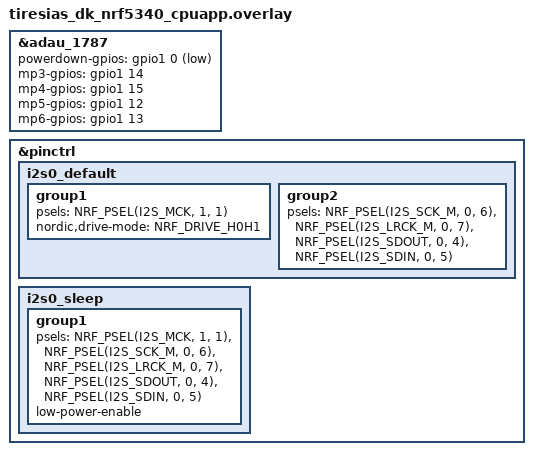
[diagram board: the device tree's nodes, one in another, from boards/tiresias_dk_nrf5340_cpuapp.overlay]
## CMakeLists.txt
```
#
# Copyright (c) 2022 Nordic Semiconductor ASA
#
# SPDX-License-Identifier: LicenseRef-Nordic-5-Clause
#

cmake_minimum_required(VERSION 3.20.0)

# Flag which defines whether application is compiled as gateway/dongle or headset
add_compile_definitions(HEADSET=1)
add_compile_definitions(GATEWAY=2)

find_package(Zephyr REQUIRED HINTS $ENV{ZEPHYR_BASE})

project(new-tiresias)

# The HA soak profile only programs the ADAU1787 and then lets the application
# core fall through to Zephyr's idle thread. Keep the normal application source
# graph untouched for the BLE profiles.
if(CONFIG_TIRESIAS_SOAK_PROFILE_HA)
  target_sources(app PRIVATE src/modes/main_ha.c)

  zephyr_library_include_directories(
      src/drivers
      src/utils/macros
      src/SigmaStudioFiles
  )

  add_subdirectory(src/drivers)
  add_subdirectory(src/SigmaStudioFiles)
elseif(CONFIG_TIRESIAS_SOAK_PROFILE_ADAU_PD)
  target_sources(app PRIVATE src/modes/main_adau_pd.c)
elseif(CONFIG_TIRESIAS_SOAK_PROFILE_ADAU_AWAKE_IDLE)
  target_sources(app PRIVATE src/modes/main_adau_awake_idle.c)
elseif(CONFIG_TIRESIAS_SOAK_PROFILE_BASELINE)
  target_sources(app PRIVATE src/modes/main_baseline.c)
else()
  string(TIMESTAMP NRF5340_AUDIO_CORE_APP_COMP_DATE "%a %b %d %H:%M:%S %Y")

# Generate fw_info_app.c
configure_file("${CMAKE_CURRENT_SOURCE_DIR}/src/utils/fw_info_app.c.in"
               "${CMAKE_BINARY_DIR}/fw_info_app.c"
               @ONLY)

# Target sources below are specific to the nRF5340 Audio DK HW
target_sources(app PRIVATE
    ${CMAKE_BINARY_DIR}/fw_info_app.c
    )

target_sources(app PRIVATE src/main.c)

# Include application events and configuration headers
zephyr_library_include_directories(
    include
    src/audio
    src/application
    src/bluetooth
    src/drivers
    src/modules
    src/utils
    src/utils/macros
    src/SigmaStudioFiles
)

zephyr_library_include_directories(app PRIVATE
    ${ZEPHYR_NRF_MODULE_DIR}/boards/arm/nrf5340_audio_dk_nrf5340)

# Application sources
add_subdirectory(src/audio)
add_subdirectory(src/application)
add_subdirectory(src/bluetooth)
add_subdirectory(src/drivers)
add_subdirectory(src/modules)
add_subdirectory(src/utils)
add_subdirectory(src/SigmaStudioFiles)
endif()
```

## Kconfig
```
#
# Copyright (c) 2018 Nordic Semiconductor ASA
#
# SPDX-License-Identifier: LicenseRef-Nordic-5-Clause
#

config TIRESIAS_SOAK_PROFILE_HA
	bool "Minimal hearing-aid soak-test image"
	help
	  Program the ADAU1787 over I2C and then leave the nRF5340 application
	  core idle with the I2C controller suspended. Bluetooth, the network core
	  and the nRF I2S peripheral are intentionally not part of this profile;
	  the ADAU1787 receives MCLK from the board's external oscillator.

config TIRESIAS_SOAK_PROFILE_BASELINE
	bool "VDD-domain baseline soak-test image"
	help
	  Leave the ADAU1787 untouched and return immediately to the Zephyr idle
	  thread. This profile is intended for direct-VDD measurements on the board
	  without the PMIC, before enabling VSYS/AVDD-dependent circuitry.

config TIRESIAS_SOAK_PROFILE_ADAU_PD
	bool "ADAU1787 power-down soak-test image"
	help
	  Keep all board supply rails present, explicitly assert the active-low
	  ADAU1787 !PD input, initialize and suspend the control I2C bus, and then
	  leave the nRF5340 application core idle. This profile performs no I2C
	  transfer and does not download a SigmaStudio program.

config TIRESIAS_SOAK_PROFILE_ADAU_AWAKE_IDLE
	bool "ADAU1787 awake-idle soak-test image"
	help
	  Release the active-low ADAU1787 !PD input, retain control-port access,
	  explicitly disable every block-level power control, suspend the I2C bus,
	  and then leave the nRF5340 application core idle. No SigmaStudio program
	  is downloaded.

config TIRESIAS_HA_INPUT_ADC
	int "ADAU1787 analog input used by the HA soak profile"
	depends on TIRESIAS_SOAK_PROFILE_HA
	range 0 1
	default 0
	help
	  Select ADC0/MICBIAS0 for the MIC0_OUT microphone or ADC1/MICBIAS1 for
	  MIC1_OUT. The Tiresias microphones are wired to AIN0 and AIN1.

config TIRESIAS_HA_OUTPUT_DAC
	int "ADAU1787 mono playback channel used by the HA soak profile"
	depends on TIRESIAS_SOAK_PROFILE_HA
	range 0 1
	default 0
	help
	  Select playback/headphone channel 0 or 1. The other channel is muted and
	  powered down after the SigmaStudio download.

menuconfig NRF5340_AUDIO
	 bool "nRF5340 Audio [EXPERIMENTAL]"
	 depends on !TIRESIAS_SOAK_PROFILE_HA && !TIRESIAS_SOAK_PROFILE_BASELINE && !TIRESIAS_SOAK_PROFILE_ADAU_PD && !TIRESIAS_SOAK_PROFILE_ADAU_AWAKE_IDLE
	 select EXPERIMENTAL

if NRF5340_AUDIO

config CUSTOM_BROADCASTER
	bool "Allow custom broadcasters"
	default n
	help
	  Incomplete feature for now, but will introduce support for multiple BIGs and subgroups.

config AUDIO_DEV
	int "Select which device type to compile for. 1=HEADSET or 2=GATEWAY"
	range 1 2
	default 1
	help
	  Setting this variable to 1 selects that the project is compiled
	  as a HEADSET device.
	  Setting to 2 will compile as a GATEWAY.

choice NRF5340_AUDIO_TRANSPORT_MODE
	prompt "Choose BIS or CIS for ISO transport"
	default TRANSPORT_CIS if WALKIE_TALKIE_DEMO
	default TRANSPORT_CIS

config TRANSPORT_BIS
	bool "Use BIS (Broadcast Isochronous Stream)"

config TRANSPORT_CIS
	bool "Use CIS (Connected Isochronous Stream)"

endchoice

#----------------------------------------------------------------------------#
rsource "Kconfig.defaults"
rsource "src/audio/Kconfig"
rsource "src/bluetooth/Kconfig"
rsource "src/drivers/Kconfig"
rsource "src/modules/Kconfig"
rsource "src/utils/Kconfig"

#----------------------------------------------------------------------------#
menu "Logging"

module = MAIN
module-str = main
source "subsys/logging/Kconfig.template.log_config"

config PRINT_STACK_USAGE_MS
	depends on THREAD_ANALYZER && INIT_STACKS
	int "Print stack usage every x milliseconds"
	default 5000

endmenu # Log levels

#----------------------------------------------------------------------------#
endif # NRF5340_AUDIO

source "Kconfig.zephyr"
```

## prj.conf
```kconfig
#
# Copyright (c) 2024 Nordic Semiconductor ASA
#
# SPDX-License-Identifier: LicenseRef-Nordic-5-Clause
#

# nRF5340 Audio
CONFIG_NRF5340_AUDIO=y
CONFIG_SAMPLE_RATE_CONVERTER=y
CONFIG_SAMPLE_RATE_CONVERTER_FILTER_SIMPLE=y

# General
CONFIG_DEBUG=y
CONFIG_DEBUG_INFO=y
CONFIG_ASSERT=y
CONFIG_STACK_USAGE=y
CONFIG_THREAD_RUNTIME_STATS=y
CONFIG_STACK_SENTINEL=y
CONFIG_INIT_STACKS=y
CONFIG_BT=y

# Uart driver
CONFIG_SERIAL=y

# Logging
CONFIG_LOG=y
CONFIG_NEWLIB_LIBC_FLOAT_PRINTF=y
CONFIG_LOG_TAG_MAX_LEN=2
CONFIG_LOG_TAG_DEFAULT="--"
CONFIG_LOG_BACKEND_UART=n
CONFIG_LOG_BACKEND_RTT=y
CONFIG_LOG_BUFFER_SIZE=4096

# Use this for debugging thread usage
#CONFIG_LOG_THREAD_ID_PREFIX=y

# Console related defines
CONFIG_CONSOLE=y
CONFIG_RTT_CONSOLE=y
CONFIG_UART_CONSOLE=n
CONFIG_SEGGER_RTT_BUFFER_SIZE_UP=8192

# Shell related defines
CONFIG_SHELL=y
CONFIG_KERNEL_SHELL=y
CONFIG_USE_SEGGER_RTT=y
CONFIG_SHELL_BACKEND_RTT=n
CONFIG_SHELL_BACKEND_SERIAL=n
CONFIG_SHELL_VT100_COMMANDS=y
CONFIG_SHELL_VT100_COLORS=y
CONFIG_SHELL_STACK_SIZE=4096
CONFIG_SHELL_CMD_BUFF_SIZE=128
## Reduce shell memory usage
CONFIG_SHELL_WILDCARD=n
CONFIG_SHELL_HELP_ON_WRONG_ARGUMENT_COUNT=n
CONFIG_SHELL_STATS=n
CONFIG_SHELL_CMDS=n
CONFIG_SHELL_HISTORY=y

# Turn off default shell commands
CONFIG_I2C_SHELL=n
CONFIG_HWINFO_SHELL=n
CONFIG_CLOCK_CONTROL_NRF_SHELL=n
CONFIG_FLASH_SHELL=n
CONFIG_DEVICE_SHELL=n

# Suppress LOG_ERR messages from sd_check_card_type. Because SPI_SDHC has no card presence method,
# assume card is in slot. Thus error message is always shown if card is not inserted
CONFIG_SD_LOG_LEVEL_OFF=y

# Suppress LOG_INF messages from hci_core
CONFIG_BT_HCI_CORE_LOG_LEVEL_WRN=y

# DFU
CONFIG_AUDIO_BT_MGMT_DFU=y
CONFIG_MCUMGR_TRANSPORT_BT_PERM_RW=y
CONFIG_BT_L2CAP_TX_MTU=498
CONFIG_BT_BUF_ACL_TX_SIZE=251

# External Flash
CONFIG_FLASH=y
CONFIG_FLASH_MAP=y
CONFIG_SPI_NOR=y
CONFIG_SPI_NOR_SFDP_DEVICETREE=y

# ====================== Broadcast Sink ====================== #

CONFIG_TRANSPORT_BIS=y
CONFIG_AUDIO_DEV=1
CONFIG_BT_DEVICE_NAME="TIRESIAS_BIS_HEADSET"

## ACL related configs ##
CONFIG_BT_OBSERVER=y
CONFIG_BT_PERIPHERAL=y
CONFIG_BT_SMP=y
CONFIG_BT_AUDIO=y
CONFIG_BT_GATT_DYNAMIC_DB=y
CONFIG_BT_GATT_CACHING=n

## Device Information Service
CONFIG_BT_DIS=y
CONFIG_BT_DIS_MANUF_NAME=y
CONFIG_BT_DIS_MANUF_NAME_STR="EESC-USP"
CONFIG_BT_DIS_MODEL_NUMBER=y
CONFIG_BT_DIS_MODEL_NUMBER_STR="Tiresias Hearing Aid"
CONFIG_BT_DIS_FW_REV=y

CONFIG_SETTINGS=y
CONFIG_BT_SETTINGS=y
CONFIG_FLASH=y
CONFIG_FLASH_MAP=y
CONFIG_NVS=y

CONFIG_MBEDTLS_ENABLE_HEAP=y
CONFIG_MBEDTLS_HEAP_SIZE=2048

CONFIG_BT_BUF_ACL_TX_COUNT=18

CONFIG_BT_PERIPHERAL_PREF_MIN_INT=64
CONFIG_BT_PERIPHERAL_PREF_MAX_INT=69
CONFIG_BT_PERIPHERAL_PREF_LATENCY=0
CONFIG_BT_PERIPHERAL_PREF_TIMEOUT=200

# Generic Audio Sink - 0x0840
CONFIG_BT_DEVICE_APPEARANCE=2112
CONFIG_BT_PER_ADV_SYNC_MAX=2

## ISO related configs ##
CONFIG_BT_BAP_BROADCAST_SNK_STREAM_COUNT=2
CONFIG_BT_BAP_BROADCAST_SNK_COUNT=2
CONFIG_BT_ISO_MAX_CHAN=2
CONFIG_BT_ISO_MAX_BIG=2

## PACS related configs ##
CONFIG_BT_PAC_SNK_NOTIFIABLE=y
CONFIG_BT_PAC_SNK=y
CONFIG_BT_PAC_SRC_NOTIFIABLE=y
CONFIG_BT_PAC_SRC=y

## Audio related configs ##
CONFIG_AUDIO_MUTE=n
CONFIG_AUDIO_TEST_TONE=y

CONFIG_BT_ISO_SYNC_RECEIVER=y
CONFIG_BT_BAP_SCAN_DELEGATOR=y
CONFIG_BT_BAP_BROADCAST_SINK=y

## LC3 related configs ##
CONFIG_LC3_DEC_CHAN_MAX=1
```

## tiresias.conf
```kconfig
# I2S
CONFIG_I2S=n
CONFIG_NRFX_I2S0=y
CONFIG_I2S_NRFX=n
CONFIG_SERIAL=y
# Bluetooth
CONFIG_BT=y
CONFIG_BT_PERIPHERAL=y
CONFIG_BT_DEVICE_NAME="Tiresias_DK"
CONFIG_BT_GATT_DYNAMIC_DB=y
CONFIG_BT_SMP=y
## Device Information Service
CONFIG_BT_DIS=y
CONFIG_BT_DIS_MANUF_NAME=y
CONFIG_BT_DIS_MANUF_NAME_STR="EESC-USP"
CONFIG_BT_DIS_MODEL_NUMBER=y
CONFIG_BT_DIS_MODEL_NUMBER_STR="Tiresias Hearing Aid"
CONFIG_BT_DIS_FW_REV=y
## Battery Service
CONFIG_BT_BAS=y
# https://docs.nordicsemi.com/bundle/zephyr-apis-latest/page/group_bt_bas.html
# CONFIG_BT_AUDIO=y
# CONFIG_BT_BAP_BROADCAST_SINK=y
# CONFIG_BT_ISO=y
# MCUMGR
CONFIG_MCUMGR=y
CONFIG_MCUMGR_TRANSPORT_BT=y
CONFIG_MCUMGR_GRP_OS=y
CONFIG_MCUMGR_GRP_IMG=y
CONFIG_MCUMGR_GRP_SHELL=y
CONFIG_STATS=y
CONFIG_MCUMGR_GRP_STAT=y
CONFIG_SHELL=y
CONFIG_BT_SHELL=y
CONFIG_SHELL_BACKEND_DUMMY=y
# GPIO
CONFIG_GPIO=y
# Debug
CONFIG_DEBUG_THREAD_INFO=y
CONFIG_DEBUG_OPTIMIZATIONS=y
# Log
CONFIG_LOG=y
CONFIG_LOG_MODE_DEFERRED=n
# Enable RTT
CONFIG_USE_SEGGER_RTT=y
CONFIG_LOG_BACKEND_RTT=y
CONFIG_LOG_BACKEND_SHOW_COLOR=n
CONFIG_LOG_MODE_IMMEDIATE=n
CONFIG_SEGGER_RTT_BUFFER_SIZE_UP=8192
# Enables console over RTT
CONFIG_RTT_CONSOLE=y
# ZBUS
CONFIG_ZBUS=y
CONFIG_ZBUS_LOG_LEVEL_INF=y
CONFIG_ZBUS_RUNTIME_OBSERVERS=y
# Stacks and heaps
CONFIG_MAIN_STACK_SIZE=16384
CONFIG_HEAP_MEM_POOL_SIZE=16384
# I2C
CONFIG_I2C=y
CONFIG_NRFX_TWIM1=y
CONFIG_NRFX_TIMER1=y
# NFC pins disable
# CONFIG_NFCT_PINS_AS_GPIOS=y
# Storage
CONFIG_FLASH=y
CONFIG_FLASH_MAP=y
CONFIG_NVS=y
CONFIG_MPU_ALLOW_FLASH_WRITE=y
# Tiresias
# CONFIG_NO_AUDIO_CODEC=y
CONFIG_AUDIO_CODEC_ADAU1787=y
# FOTA
CONFIG_NCS_SAMPLE_MCUMGR_BT_OTA_DFU=y
CONFIG_PINCTRL=y
```

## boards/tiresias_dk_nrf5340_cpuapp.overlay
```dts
/* Temporary pin swap until the SPT0 data path is repaired. */

&adau_1787 {
	powerdown-gpios = <&gpio1 0 GPIO_ACTIVE_LOW>;
	mp3-gpios = <&gpio1 14 GPIO_ACTIVE_HIGH>;
	mp4-gpios = <&gpio1 15 GPIO_ACTIVE_HIGH>;
	mp5-gpios = <&gpio1 12 GPIO_ACTIVE_HIGH>;
	mp6-gpios = <&gpio1 13 GPIO_ACTIVE_HIGH>;
};

&pinctrl {
	i2s0_default: i2s0_default {
		group1 {
			psels = <NRF_PSEL(I2S_MCK, 1, 1)>;
			nordic,drive-mode = <NRF_DRIVE_H0H1>;
		};

		group2 {
			psels = <NRF_PSEL(I2S_SCK_M, 0, 6)>,
				<NRF_PSEL(I2S_LRCK_M, 0, 7)>,
				<NRF_PSEL(I2S_SDOUT, 0, 4)>,
				<NRF_PSEL(I2S_SDIN, 0, 5)>;
		};
	};

	i2s0_sleep: i2s0_sleep {
		group1 {
			psels = <NRF_PSEL(I2S_MCK, 1, 1)>,
				<NRF_PSEL(I2S_SCK_M, 0, 6)>,
				<NRF_PSEL(I2S_LRCK_M, 0, 7)>,
				<NRF_PSEL(I2S_SDOUT, 0, 4)>,
				<NRF_PSEL(I2S_SDIN, 0, 5)>;
			low-power-enable;
		};
	};
};
```

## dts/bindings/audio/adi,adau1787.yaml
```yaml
description: Analog Devices ADAU1787 audio codec and DSP

compatible: "adi,adau1787"

include: i2c-device.yaml

properties:
  powerdown-gpios:
    type: phandle-array
    required: true
    description: Active-low ADAU1787 power-down input

  mp3-gpios:
    type: phandle-array
    description: ADAU1787 multipurpose pin 3 connection

  mp4-gpios:
    type: phandle-array
    description: ADAU1787 multipurpose pin 4 connection

  mp5-gpios:
    type: phandle-array
    description: ADAU1787 multipurpose pin 5 connection

  mp6-gpios:
    type: phandle-array
    description: ADAU1787 multipurpose pin 6 connection
```

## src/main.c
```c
/*
 * Copyright (c) 2023 Nordic Semiconductor ASA
 *
 * SPDX-License-Identifier: LicenseRef-Nordic-5-Clause
 */

#include "device_controller.h"
#include "fw_info_app.h"
#include "macros_common.h"
#include "tiresias_dk.h"

#include <zephyr/logging/log.h>

LOG_MODULE_REGISTER(main, CONFIG_MAIN_LOG_LEVEL);

int main(void)
{
  int ret;

  LOG_DBG("Main started");

  ret = tiresias_dk_init();
  ERR_CHK(ret);

  ret = fw_info_app_print();
  ERR_CHK(ret);

  ret = device_controller_run();
  ERR_CHK(ret);

  return ret;
}
```

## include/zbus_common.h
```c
/*
 * Copyright (c) 2023 Nordic Semiconductor ASA
 *
 * SPDX-License-Identifier: LicenseRef-Nordic-5-Clause
 */

#ifndef _ZBUS_COMMON_H_
#define _ZBUS_COMMON_H_

#include <zephyr/bluetooth/audio/audio.h>

#include "le_audio.h"

#define ZBUS_READ_TIMEOUT_MS	K_MSEC(100)
#define ZBUS_ADD_OBS_TIMEOUT_MS K_MSEC(200)

/***** Messages for zbus ******/

/* === Button === */
typedef enum btn_event_t {
	BUTTON_1_PRESSED,
} btn_event_t;
typedef struct btn_chan_msg_t {
	enum btn_event_t event;
} btn_chan_msg_t;

/* === Device Controller subsystem === */
typedef enum device_controller_cmd {
  DEVICE_CONTROLLER_CMD_START,
  DEVICE_CONTROLLER_CMD_LOW_POWER,
  DEVICE_CONTROLLER_CMD_WAKE,
  DEVICE_CONTROLLER_CMD_POWER_OFF,
  DEVICE_CONTROLLER_CMD_RECOVER,
} device_controller_cmd;

typedef struct device_controller_cmd_chan_msg {
  enum device_controller_cmd cmd;
} device_controller_cmd_chan_msg;

typedef enum device_controller_state {
  DEVICE_CONTROLLER_STATE_OFF,
  DEVICE_CONTROLLER_STATE_INITIALIZING,
  DEVICE_CONTROLLER_STATE_OPERATIONAL,
  DEVICE_CONTROLLER_STATE_LOW_POWER,
  DEVICE_CONTROLLER_STATE_FAULT,
} device_controller_state;

typedef struct device_controller_state_chan_msg {
  enum device_controller_state state;
} device_controller_state_chan_msg;

/* === Codec Controller subsystem === */
typedef enum codec_controller_cmd {
  CODEC_CONTROLLER_CMD_INITIALIZE,
  CODEC_CONTROLLER_CMD_SELECT_LOCAL,
  CODEC_CONTROLLER_CMD_SELECT_BROADCAST,
  CODEC_CONTROLLER_CMD_POWER_DOWN,
  CODEC_CONTROLLER_CMD_RESET,
} codec_controller_cmd;

typedef struct codec_controller_cmd_chan_msg {
  enum codec_controller_cmd cmd;
} codec_controller_cmd_chan_msg;

typedef enum codec_controller_state {
  CODEC_CONTROLLER_STATE_OFF,
  CODEC_CONTROLLER_STATE_INITIALIZING,
  CODEC_CONTROLLER_STATE_LOCAL_ONLY,
  CODEC_CONTROLLER_STATE_BROADCAST_ONLY,
  CODEC_CONTROLLER_STATE_ERROR,
} codec_controller_state;

typedef struct codec_controller_state_chan_msg {
  enum codec_controller_state state;
} codec_controller_state_chan_msg;

typedef enum codec_controller_result {
  CODEC_CONTROLLER_RESULT_COMMAND_REJECTED,
  CODEC_CONTROLLER_RESULT_OPERATION_FAILED,
} codec_controller_result;

typedef struct codec_controller_result_chan_msg {
  enum codec_controller_cmd cmd;
  enum codec_controller_result result;
  int error;
} codec_controller_result_chan_msg;

/* === Control Link subsystem === */
typedef enum control_link_cmd {
  CONTROL_LINK_CMD_ENABLE_CONTROL,
  CONTROL_LINK_CMD_DISABLE_CONTROL,
  CONTROL_LINK_CMD_RESET,
} control_link_cmd;

typedef struct control_link_cmd_chan_msg {
  enum control_link_cmd cmd;
} control_link_cmd_chan_msg;

typedef enum control_link_state {
  CONTROL_LINK_STATE_DISABLED,
  CONTROL_LINK_STATE_ADVERTISING,
  CONTROL_LINK_STATE_CONNECTED,
  CONTROL_LINK_STATE_ERROR,
} control_link_state;

typedef struct control_link_state_chan_msg {
  enum control_link_state state;
} control_link_state_chan_msg;

typedef enum control_link_result {
  CONTROL_LINK_RESULT_COMMAND_REJECTED,
  CONTROL_LINK_RESULT_OPERATION_FAILED,
} control_link_result;

typedef struct control_link_event_chan_msg {
  enum control_link_cmd cmd;
  enum control_link_result result;
  int error;
} control_link_event_chan_msg;

/* === Audio Streaming subsystem === */
typedef enum audio_streaming_cmd {
  AUDIO_STREAMING_CMD_ENABLE_RECEIVER,
  AUDIO_STREAMING_CMD_START_SCAN,
  AUDIO_STREAMING_CMD_STOP_SCAN,
  AUDIO_STREAMING_CMD_STOP,
  AUDIO_STREAMING_CMD_DISABLE_RECEIVER,
  AUDIO_STREAMING_CMD_RESET,
} audio_streaming_cmd;

typedef struct audio_streaming_cmd_chan_msg {
  enum audio_streaming_cmd cmd;
} audio_streaming_cmd_chan_msg;

typedef enum audio_streaming_state {
  AUDIO_STREAMING_STATE_DISABLED,
  AUDIO_STREAMING_STATE_IDLE,
  AUDIO_STREAMING_STATE_SCANNING,
  AUDIO_STREAMING_STATE_PA_SYNCED,
  AUDIO_STREAMING_STATE_BIS_SYNCING,
  AUDIO_STREAMING_STATE_STREAMING,
  AUDIO_STREAMING_STATE_RECOVERING,
  AUDIO_STREAMING_STATE_ERROR,
} audio_streaming_state;

typedef struct audio_streaming_state_chan_msg {
  enum audio_streaming_state state;
} audio_streaming_state_chan_msg;

typedef enum audio_streaming_result {
  AUDIO_STREAMING_RESULT_COMMAND_REJECTED,
  AUDIO_STREAMING_RESULT_OPERATION_FAILED,
} audio_streaming_result;

typedef struct audio_streaming_result_chan_msg {
  enum audio_streaming_cmd cmd;
  enum audio_streaming_result result;
  int error;
} audio_streaming_result_chan_msg;

/* === LED === */
typedef enum board_led_t {
  LED_1,
  LED_2,
  LED_3,
} board_led_t;
typedef enum led_cmd_t {
  TURN_ON,
  TURN_OFF,
  TOGGLE,
  BLINK,
} led_cmd_t;
typedef struct led_chan_msg_t {
  enum board_led_t led;
  enum led_cmd_t cmd;
} led_chan_msg_t;

enum le_audio_evt_type {
	LE_AUDIO_EVT_CONFIG_RECEIVED = 1,
	LE_AUDIO_EVT_PRES_DELAY_SET,
	LE_AUDIO_EVT_STREAMING,
	LE_AUDIO_EVT_NOT_STREAMING,
	LE_AUDIO_EVT_STREAM_SENT,
	LE_AUDIO_EVT_SYNC_LOST,
	LE_AUDIO_EVT_NO_VALID_CFG,
	LE_AUDIO_EVT_COORD_SET_DISCOVERED,
};

struct le_audio_msg {
	enum le_audio_evt_type event;
	struct bt_conn *conn;
	struct bt_le_per_adv_sync *pa_sync;
	enum bt_audio_dir dir;
	uint8_t set_size;
	uint8_t const *sirk;
	struct stream_index idx;
};

/**
 * tx_sync_ts_us	The timestamp from get_tx_sync.
 * curr_ts_us		The current time. This must be in the controller frame of reference.
 */
struct sdu_ref_msg {
	uint32_t tx_sync_ts_us;
	uint32_t curr_ts_us;
	bool adjust;
};

enum bt_mgmt_evt_type {
	BT_MGMT_EXT_ADV_WITH_PA_READY = 1,
	BT_MGMT_CONNECTED,
	BT_MGMT_SECURITY_CHANGED,
	BT_MGMT_PA_SYNCED,
	BT_MGMT_PA_SYNC_LOST,
	BT_MGMT_DISCONNECTED,
	BT_MGMT_BROADCAST_SINK_DISABLE,
	BT_MGMT_BROADCAST_CODE_RECEIVED,
	BT_MGMT_EXT_ADV_STARTED,
	BT_MGMT_EXT_ADV_FAILED,
};

struct bt_mgmt_msg {
	enum bt_mgmt_evt_type event;
	struct bt_conn *conn;
	bool peripheral;
	uint8_t index;
	struct bt_le_ext_adv *ext_adv;
	struct bt_le_per_adv_sync *pa_sync;
	uint32_t broadcast_id;
	uint8_t pa_sync_term_reason;
	int error;
};

enum volume_evt_type {
	VOLUME_UP = 1,
	VOLUME_DOWN,
	VOLUME_SET,
	VOLUME_MUTE,
	VOLUME_UNMUTE,
};

struct volume_msg {
	enum volume_evt_type event;
	uint8_t volume;
};

enum content_control_evt_type {
	MEDIA_START = 1,
	MEDIA_STOP,
};

struct content_control_msg {
	enum content_control_evt_type event;
};

#endif /* _ZBUS_COMMON_H_ */
```
